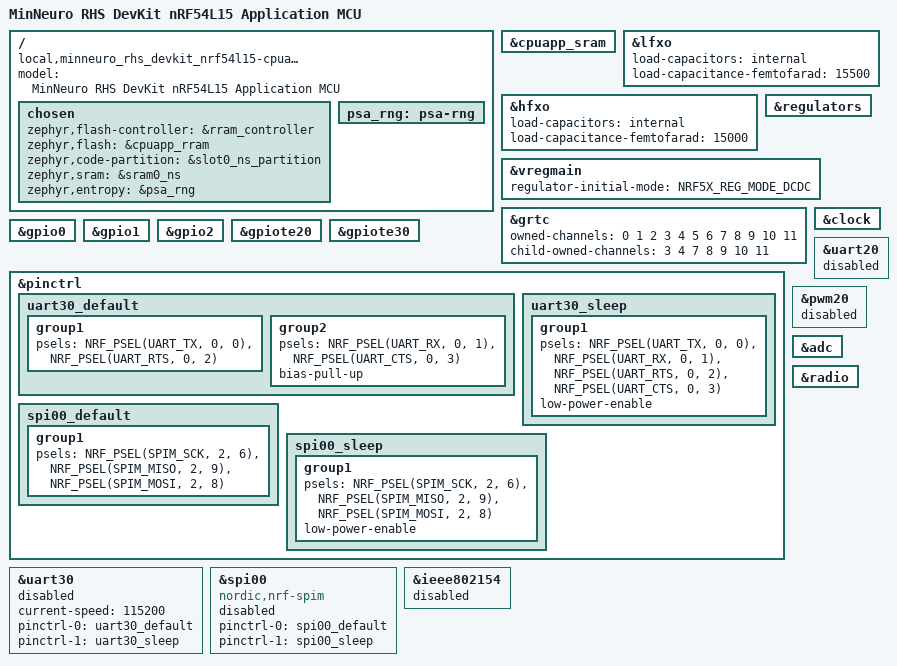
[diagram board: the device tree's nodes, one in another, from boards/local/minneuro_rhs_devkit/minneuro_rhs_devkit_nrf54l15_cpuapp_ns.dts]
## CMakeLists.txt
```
# SPDX-License-Identifier: Apache-2.0

cmake_minimum_required(VERSION 3.20.0)

list(APPEND BOARD_ROOT ${CMAKE_CURRENT_SOURCE_DIR})

find_package(Zephyr REQUIRED HINTS $ENV{ZEPHYR_BASE})
project(hello_world)

if(TARGET modules__fatfs)
  get_filename_component(FATFS_MODULE_DIR "$ENV{ZEPHYR_BASE}/../modules/fs/fatfs" ABSOLUTE)
  set_property(TARGET modules__fatfs PROPERTY SOURCES
    ${FATFS_MODULE_DIR}/ff.c
    ${FATFS_MODULE_DIR}/option/ffunicode.c
  )
  target_compile_definitions(modules__fatfs PRIVATE
    ZEPHYR_CONFIG_OVERRIDE=file_fatfs_config.h
  )
endif()

FILE(GLOB app_sources CONFIGURE_DEPENDS
  src/*.c
  src/inc/*.h
  neuro/*.c
  neuro/inc/*.h
  driver/*.c
  driver/*.h
)
# Zephyr SPI DAC shim — unused: stim uses dac80501.c + dac80501_hal via spim00_bus only.
list(FILTER app_sources EXCLUDE REGEX ".*/dac_dac80501_spi\\.c$")
target_sources(app PRIVATE ${app_sources} src/main.c)
target_include_directories(app PRIVATE ${CMAKE_CURRENT_SOURCE_DIR})
```

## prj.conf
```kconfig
# 先把所有日志/控制台关掉（很多卡死发生在串口/console init）
CONFIG_LOG=y
CONFIG_CONSOLE=n
CONFIG_UART_CONSOLE=n
CONFIG_PRINTK=y
CONFIG_SERIAL=n
CONFIG_USE_SEGGER_RTT=y
CONFIG_SHELL_BACKEND_RTT=n
# Log goes to SEGGER RTT only (UART console is disabled). Viewer must attach to Terminal 0.
# DROP mode silently discards logs when RTT FIFO is full or host attaches late — use OVERWRITE
# during bring-up so the latest lines survive in the circular buffer.
CONFIG_LOG_MODE_IMMEDIATE=y
CONFIG_SEGGER_RTT_BUFFER_SIZE_UP=32768
CONFIG_LOG_BACKEND_RTT_MODE_DROP=n
CONFIG_LOG_BACKEND_RTT_MODE_OVERWRITE=y
CONFIG_LOG_BACKEND_RTT_MESSAGE_SIZE=256

# printk/printf 支持 float
CONFIG_CBPRINTF_NANO=n
CONFIG_CBPRINTF_FP_SUPPORT=y

# flash / NVS / settings 全关
CONFIG_FLASH=n
CONFIG_FLASH_MAP=n
CONFIG_NVS=n
CONFIG_SETTINGS=n
CONFIG_FCB=n

# FatFs (ELM) — 纯库，不依赖 Zephyr SD/SPI/diskaccess 驱动
# SD SPI 协议和磁盘 I/O 完全在 driver/file.c 里自己实现
CONFIG_FILE_SYSTEM=y
CONFIG_FAT_FILESYSTEM_ELM=y
CONFIG_FS_FATFS_LFN=y
CONFIG_FS_FATFS_MAX_LFN=255
CONFIG_FS_FATFS_MOUNT_MKFS=y
CONFIG_FS_FATFS_CUSTOM_MOUNT_POINT_COUNT=1
CONFIG_FS_FATFS_CUSTOM_MOUNT_POINTS="0"

# SPIM00: spim00_bus + nrfx only (SD HAL, dac80501_hal, ks1092). DTS &spi00 disabled.
CONFIG_NRFX_SPIM=y
CONFIG_SPI=n
CONFIG_DAC=n

# 不启用 Zephyr 的 SD/MMC/diskaccess 栈
# CONFIG_DISK_DRIVER_SDMMC 和 CONFIG_SDMMC_STACK 均不开启

# 先别让任何低频时钟/外设复杂初始化影响（RC 32k，稳定）
# CONFIG_CLOCK_CONTROL=y
# CONFIG_CLOCK_CONTROL_NRF=y
# CONFIG_CLOCK_CONTROL_NRF_K32SRC_RC=y
# CONFIG_CLOCK_CONTROL_NRF_K32SRC_XTAL=n
# CONFIG_CLOCK_CONTROL_NRF_K32SRC_SYNTH=n

###########################################################

################################
# Bluetooth Core
################################
CONFIG_BT=y
CONFIG_BT_PERIPHERAL=y
CONFIG_BT_DEVICE_NAME="MinNeuro R1"

################################
# GATT / 需要 MTU 交换
################################
CONFIG_BT_GATT_CLIENT=y

################################
# PHY / DLE
################################
CONFIG_BT_CTLR_PHY_2M=y
CONFIG_BT_USER_PHY_UPDATE=y

CONFIG_BT_USER_DATA_LEN_UPDATE=y
CONFIG_BT_CTLR_DATA_LENGTH_MAX=251

################################
# MTU = 500（关键）
################################
CONFIG_BT_L2CAP_TX_MTU=500


# ATT MTU 交换：两边都至少 503（ATT=MTU，L2CAP/SDU 还要开销）
# Zephyr 的 ATT MTU 由 L2CAP_TX_MTU 驱动，但 buffer 也必须够
CONFIG_BT_BUF_ACL_TX_SIZE=500
CONFIG_BT_BUF_ACL_RX_SIZE=500

# 为了稳定，建议把 TX buffer 数量略抬高（默认有时不够导致 -ENOMEM）
CONFIG_BT_BUF_ACL_TX_COUNT=10
CONFIG_BT_BUF_EVT_RX_COUNT=11

# ATT TX pool buffer 数量（att_pool, 直接决定 K_NO_WAIT 下能否拿到 buffer）
# 默认 = BT_BUF_ACL_TX_COUNT。sys_work_q 上 notify 使用 K_NO_WAIT，
# 5ms × 2 char × 500B / 2M PHY pipeline 容易耗尽，需要显式扩大。
CONFIG_BT_ATT_TX_COUNT=10

################################
# Services
################################
CONFIG_BT_BAS=y
CONFIG_BT_DIS=y


################################
# DIS 信息（不走 settings）
################################
CONFIG_BT_DIS_PNP=n
CONFIG_BT_DIS_MODEL="MinNeuro R1"
CONFIG_BT_DIS_MANUF="MinNeuro"

CONFIG_BT_DIS_SERIAL_NUMBER=y
CONFIG_BT_DIS_SERIAL_NUMBER_STR="F.A000001"

CONFIG_BT_DIS_FW_REV=y
CONFIG_BT_DIS_FW_REV_STR="MinNeuro Firmware"
CONFIG_BT_DIS_HW_REV=y
CONFIG_BT_DIS_HW_REV_STR="MinNeuro Hardware"
CONFIG_BT_DIS_SW_REV=y
CONFIG_BT_DIS_SW_REV_STR="MinNeuro Software"

CONFIG_BT_DIS_STR_MAX=32

################################
# ❌ 明确关闭 settings（否则必炸）
################################
CONFIG_BT_SETTINGS=n
CONFIG_SETTINGS=n
CONFIG_BT_DIS_SETTINGS=n


################################
# CONFIG
################################

# looper_work_handler 运行于系统工作队列线程，适当加大其栈空间
CONFIG_SYSTEM_WORKQUEUE_STACK_SIZE=4096
# main 线程栈
CONFIG_MAIN_STACK_SIZE=2048

CONFIG_GPIO=y
CONFIG_PINCTRL=y
CONFIG_NRFX_SAADC=y
CONFIG_NRFX_SPIS=n

# CONFIG_NRFX_TIMER=y
# CONFIG_PINCTRL=y
# # CONFIG_I2C=y
# CONFIG_ADC=y
# CONFIG_NRFX_SAADC=y
# CONFIG_REBOOT=y
```

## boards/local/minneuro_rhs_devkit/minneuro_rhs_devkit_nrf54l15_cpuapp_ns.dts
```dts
/*
 * MinNeuro RHS DevKit — nRF54L15 Application MCU, non-secure image.
 * Partition layout must stay in sync with TF-M (see Nordic
 * nrf54l15_cpuapp_ns_partition.dtsi).
 */

/dts-v1/;

#define USE_NON_SECURE_ADDRESS_MAP 1

#include <arm/nordic/nrf54l15_cpuapp_ns.dtsi>

/ {
	model = "MinNeuro RHS DevKit nRF54L15 Application MCU";
	compatible = "local,minneuro_rhs_devkit_nrf54l15-cpuapp";

	chosen {
		zephyr,flash-controller = &rram_controller;
		zephyr,flash = &cpuapp_rram;
		zephyr,code-partition = &slot0_ns_partition;
		zephyr,sram = &sram0_ns;
		zephyr,entropy = &psa_rng;
	};

	/delete-node/ rng;

	psa_rng: psa-rng {
		status = "okay";
	};
};

#include <vendor/nordic/nrf54l15_cpuapp_ns_partition.dtsi>

&cpuapp_sram {
	status = "okay";
};

&lfxo {
	load-capacitors = "internal";
	load-capacitance-femtofarad = <15500>;
};

&hfxo {
	load-capacitors = "internal";
	load-capacitance-femtofarad = <15000>;
};

&regulators {
	status = "okay";
};

&vregmain {
	status = "okay";
	regulator-initial-mode = <NRF5X_REG_MODE_DCDC>;
};

&grtc {
	owned-channels = <0 1 2 3 4 5 6 7 8 9 10 11>;
	child-owned-channels = <3 4 7 8 9 10 11>;
	status = "okay";
};

&clock {
	status = "okay";
};

&gpio0 {
	status = "okay";
};

&gpio1 {
	status = "okay";
};

&gpio2 {
	status = "okay";
};

&gpiote20 {
	status = "okay";
};

&gpiote30 {
	status = "okay";
};

&pinctrl {
	/* TF-M secure image uses UARTE30; match nRF54L15 DK pins unless your schematic differs. */
	uart30_default: uart30_default {
		group1 {
			psels = <NRF_PSEL(UART_TX, 0, 0)>,
				<NRF_PSEL(UART_RTS, 0, 2)>;
		};

		group2 {
			psels = <NRF_PSEL(UART_RX, 0, 1)>,
				<NRF_PSEL(UART_CTS, 0, 3)>;
			bias-pull-up;
		};
	};

	uart30_sleep: uart30_sleep {
		group1 {
			psels = <NRF_PSEL(UART_TX, 0, 0)>,
				<NRF_PSEL(UART_RX, 0, 1)>,
				<NRF_PSEL(UART_RTS, 0, 2)>,
				<NRF_PSEL(UART_CTS, 0, 3)>;
			low-power-enable;
		};
	};

	spi00_default: spi00_default {
		group1 {
			psels = <NRF_PSEL(SPIM_SCK, 2, 6)>,
				<NRF_PSEL(SPIM_MISO, 2, 9)>,
				<NRF_PSEL(SPIM_MOSI, 2, 8)>;
		};
	};

	spi00_sleep: spi00_sleep {
		group1 {
			psels = <NRF_PSEL(SPIM_SCK, 2, 6)>,
				<NRF_PSEL(SPIM_MISO, 2, 9)>,
				<NRF_PSEL(SPIM_MOSI, 2, 8)>;
			low-power-enable;
		};
	};
};

&uart20 {
	status = "disabled";
};

&uart30 {
	/* Disable Zephyr driver in NS; TF-M still requires this node + pinctrl for secure build. */
	status = "disabled";

	current-speed = <115200>;
	pinctrl-0 = <&uart30_default>;
	pinctrl-1 = <&uart30_sleep>;
	pinctrl-names = "default", "sleep";
};

&pwm20 {
	status = "disabled";
};

/*
 * SPIM00 is owned by application HAL: spim00_bus (SD file_nrf54_hal, dac80501_hal, ks1092).
 * Keep Zephyr &spi00 disabled so spi_nrfx does not share the same nrfx instance.
 */
&spi00 {
	compatible = "nordic,nrf-spim";
	status = "disabled";
	pinctrl-0 = <&spi00_default>;
	pinctrl-1 = <&spi00_sleep>;
	pinctrl-names = "default", "sleep";
};

&adc {
	status = "okay";
};

&radio {
	status = "okay";
};

&ieee802154 {
	status = "disabled";
};
```

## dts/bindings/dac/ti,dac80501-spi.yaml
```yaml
# Copyright (c) 2025 MinNeuro
# SPDX-License-Identifier: Apache-2.0

description: |
  TI DAC80501 16-bit DAC (SPI variant).
  SPI frame format: 24-bit (8-bit register address + 16-bit data).
  CPOL=0, CPHA=1 (SPI mode 1).

compatible: "ti,dac80501-spi"

include: [dac-controller.yaml, spi-device.yaml]

properties:
  voltage-reference:
    type: string
    required: true
    enum:
      - "internal"
      - "external"
    description: |
      DAC voltage reference select: either internal (2.5 V) or external.

  output-gain:
    type: string
    required: true
    enum:
      - "mul2"
      - "mul1"
      - "div2"
      - "div2-x2"
    description: |
      Output voltage range control.
        mul2:    VREF * 2 (buffer gain 2x, ref divider off)  → 5.0 V
        mul1:    VREF * 1 (buffer gain 1x, ref divider off)  → 2.5 V
        div2:    VREF / 2 (buffer gain 1x, ref divider on)   → 1.25 V
        div2-x2: VREF/2 * 2 (ref divider on + buffer gain 2x) → 2.5 V
                 Safe for 3.3 V rails (avoids REF-ALARM).
```

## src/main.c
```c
#include <zephyr/kernel.h>
#include <zephyr/logging/log.h>
#include <zephyr/sys/printk.h>

#include "driver/spim00_bus.h"
#include "inc/sd_fs_test.h"
#include "inc/stim_test.h"

#include "neuro/inc/neuro_ctrl.h"

LOG_MODULE_REGISTER(main_app, LOG_LEVEL_INF);

int main(void)
{
  int err;

  k_msleep(300); /* Wait for power to stabilize */

  printk("\n>>> main alive (printk to RTT; UART console disabled)\n");

  /* One-time SPIM00 (nrfx) init before any EEG / stim / SD task touches the bus (idempotent). */
  err = spim00_bus_init();
  if (err != 0) {
    LOG_ERR("spim00_bus_init failed (%d)", err);
  }

  /*
   * SPI / bus stress layout (adjust priorities vs. sd_fs_test / driver mutex):
   *   sd_fs_test  — mount + FAT I/O on SPIM00 (prio 3, sd_fs_test.c)
   *   eeg_test    — eeg_manager timer + frame reads (prio 5, eeg_test.c)
   *   stim_test   — DAC / neuro waveform on SPI (prio 6, stim_test.c)
   *
   * Real concurrency correctness depends on spim00_bus (or Zephyr spi00)
   * arbitration and chip-select isolation; these threads deliberately overlap.
   */
  // LOG_INF("=== start SD FAT smoke thread ===");
  err = sd_fs_test_start();
  if (err != 0) {
    LOG_ERR("sd_fs_test_start failed (%d)", err);
  }

  // LOG_INF("=== start EEG test thread ===");
  // err = eeg_test_start();
  // if (err != 0) {
  //   LOG_ERR("eeg_test_start failed (%d)", err);
  // }

  // LOG_INF("=== start stim test thread ===");
  // err = stim_test_start();
  // if (err != 0) {
  //   LOG_ERR("stim_test_start failed (%d)", err);
  // }

  /*
   * Enables neuro_ctrl_thread_main idle→run: sets running=true after neuro_ctrl_init.
   * Idempotent init if stim_test_start already succeeded; retries init if stim failed earlier.
   * Note: simultaneous stim_test DAC streaming and neuro wave_ctrl DAC use must be coordinated.
   */
  // err = neuro_ctrl_start();
  if (err != 0) {
    LOG_ERR("neuro_ctrl_start failed (%d)", err);
  } else {
    LOG_INF("neuro_ctrl main loop enabled (running=true)");
  }

  for (;;) {
    //LOG_INF("keep working :(");
    k_sleep(K_FOREVER);
  }
//never reach here
  return 0;
}
```

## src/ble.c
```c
#include "inc/ble.h"

#include "inc/minneuro_mode.h"

#include <zephyr/sys/util.h>
#include <zephyr/settings/settings.h>
#include <zephyr/bluetooth/bluetooth.h>
#include <zephyr/bluetooth/gatt.h>
#include <zephyr/logging/log.h>

#include "inc/ble_conn.h"
#include "inc/ble_bat.h"
#include "inc/ble_debug.h"
#include "inc/ble_aaaa.h"

LOG_MODULE_REGISTER(ble, LOG_LEVEL_INF);

void mtu_updated(struct bt_conn *conn, uint16_t tx, uint16_t rx)
{
	printk("Updated MTU: TX: %d RX: %d bytes\n", tx, rx);
}
static struct bt_gatt_cb gatt_callbacks = {.att_mtu_updated = mtu_updated};

int ble_init()
{
  int err = 0;
  
  // Bluetooth
  err = bt_enable(NULL);
  if (err) {
    return err;
  }
  bt_gatt_cb_register(&gatt_callbacks);
  // // // LOG_INF("Bluetooth init success.");
  // // if (IS_ENABLED(CONFIG_BT_SETTINGS))
  // // {
  // //   settings_load();
  // //   // LOG_INF("Settings init success.");
  // // }

  err = ble_aaaa_init();
  if (err) {
    return err;
  }

#if MINNEURO_DEBUG_MODE && !MINNEURO_STIM_TEST_MODE
  err = ble_debug_init();
  if (err) {
    LOG_WRN("debug BLE service init failed (%d), continuing without debug service", err);
  }
#endif

  err = ble_bat_init();
  if (err) {
    err = 0;
  }
  
  err = ble_adv_init();
  if (err) {
    return err;
  }
  
  err = ble_adv_start();
  if (err) {
    return err;
  }

  return 0;
}

int ble_uninit()
{
  return 0;
}
```

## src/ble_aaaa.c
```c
#ifndef ENABLE_FACA_SERVICE__
#define ENABLE_FACA_SERVICE__

#include "inc/ble_aaaa_priv.h"

#include "inc/bsp.h"
#include "neuro/inc/eeg_manager.h"

#include <zephyr/bluetooth/bluetooth.h>
#include <zephyr/bluetooth/hci.h>
#include <zephyr/bluetooth/conn.h>
#include <zephyr/bluetooth/uuid.h>
#include <zephyr/bluetooth/gatt.h>

#include <zephyr/logging/log.h>
LOG_MODULE_REGISTER(aaaa, LOG_LEVEL_INF);


/*
 **************************************************
 *                                                *
 *  Bluetooth LE.                                 *
 *                                                *
 **************************************************
 */

// SERVICE: AAAA
struct bt_uuid_128 aaaa_service_uuid = BT_UUID_INIT_128(BT_UUID_128_ENCODE(0x0000AAAA, 0x0000, 0x1000, 0x8000, 0x00805f9b34fb));

// EMG/ECG/EOG/EEG Characteristics
//// AAF0: READ STATE
struct bt_uuid_128 aaf0_char_uuid = BT_UUID_INIT_128(BT_UUID_128_ENCODE(0x0000AAF0, 0x0000, 0x1000, 0x8000, 0x00805f9b34fb));
//// AAFF: STREAM
struct bt_uuid_128 aaff_char_uuid = BT_UUID_INIT_128(BT_UUID_128_ENCODE(0x0000AAFF, 0x0000, 0x1000, 0x8000, 0x00805f9b34fb));

// IMU/MAG Characteristics
//// AAE0: READ STATE
struct bt_uuid_128 aae0_char_uuid = BT_UUID_INIT_128(BT_UUID_128_ENCODE(0x0000AAE0, 0x0000, 0x1000, 0x8000, 0x00805f9b34fb));
//// AAEF: STREAM
struct bt_uuid_128 aaef_char_uuid = BT_UUID_INIT_128(BT_UUID_128_ENCODE(0x0000AAEF, 0x0000, 0x1000, 0x8000, 0x00805f9b34fb));

// PPG Characteristics
//// AAD0: READ STATE
struct bt_uuid_128 aad0_char_uuid = BT_UUID_INIT_128(BT_UUID_128_ENCODE(0x0000AAD0, 0x0000, 0x1000, 0x8000, 0x00805f9b34fb));
//// AADF: STREAM
struct bt_uuid_128 aadf_char_uuid = BT_UUID_INIT_128(BT_UUID_128_ENCODE(0x0000AADF, 0x0000, 0x1000, 0x8000, 0x00805f9b34fb));


BT_GATT_SERVICE_DEFINE(aaaa_service,
  BT_GATT_PRIMARY_SERVICE(&aaaa_service_uuid),
  /** EMG/ECG/EOG/EEG **/
  // State.
  BT_GATT_CHARACTERISTIC(&aaf0_char_uuid.uuid, BT_GATT_CHRC_WRITE | BT_GATT_CHRC_WRITE_WITHOUT_RESP | BT_GATT_CHRC_NOTIFY | BT_GATT_CHRC_READ,
            BT_GATT_PERM_READ | BT_GATT_PERM_WRITE, ble_on_aaf0_read_request, ble_on_aaf0_write_request, NULL),
  BT_GATT_CCC(ble_ccc_cfg_changed_aaf0, BT_GATT_PERM_READ | BT_GATT_PERM_WRITE),
  // Stream.
  BT_GATT_CHARACTERISTIC(&aaff_char_uuid.uuid, BT_GATT_CHRC_NOTIFY | BT_GATT_CHRC_READ,
            BT_GATT_PERM_READ | BT_GATT_PERM_WRITE, NULL, NULL, NULL),
  BT_GATT_CCC(ble_ccc_cfg_changed_aaff, BT_GATT_PERM_READ | BT_GATT_PERM_WRITE),

  /** IMU/MAG **/
  // State.
  BT_GATT_CHARACTERISTIC(&aae0_char_uuid.uuid, BT_GATT_CHRC_WRITE | BT_GATT_CHRC_WRITE_WITHOUT_RESP | BT_GATT_CHRC_NOTIFY | BT_GATT_CHRC_READ,
            BT_GATT_PERM_READ | BT_GATT_PERM_WRITE, ble_on_aae0_read_request, ble_on_aae0_write_request, NULL),
  BT_GATT_CCC(ble_ccc_cfg_changed_aae0, BT_GATT_PERM_READ | BT_GATT_PERM_WRITE),
  // Stream.
  BT_GATT_CHARACTERISTIC(&aaef_char_uuid.uuid, BT_GATT_CHRC_NOTIFY | BT_GATT_CHRC_READ,
            BT_GATT_PERM_READ | BT_GATT_PERM_WRITE, NULL, NULL, NULL),
  BT_GATT_CCC(ble_ccc_cfg_changed_aaef, BT_GATT_PERM_READ | BT_GATT_PERM_WRITE),
);


/*
 **************************************************
 *                                                *
 *  Worker Loop                                 *
 *                                                *
 **************************************************
*/

static mpu_sync_frame_t sync_frame[2];
volatile int sync_frame_index = 0;
volatile bool sync_frame_ready = false;
volatile uint32_t sync_seq = 0;
static uint32_t eeg_seq = 0;

int mpu_irq_on_rx_ready(mpu_sync_frame_t * frame)
{
  /* struct 赋值 = memcpy，完整值拷贝到全局静态数组，安全。
   * frame 指向 mpu_irq.c 内的 static parsed_frame，不会随函数返回而消失。*/
  sync_frame_index = (sync_frame_index + 1) % 2;
  sync_frame[sync_frame_index] = *frame;
  sync_frame_ready = true;
  sync_seq++;
  return 0;
}

// Looper

#define LOOPER_INTERVAL         1     // 1ms

static void looper_work_handler(struct k_work *work);

static K_WORK_DELAYABLE_DEFINE(looper_work, looper_work_handler);

static void looper_work_handler(struct k_work *work)
{
  eeg_manager_frame_t eeg_frame;
  static mpu_eeg_data_t eeg_notify_frame[TASK_EEG_FRAME_SIZE];
  uint8_t eeg_samples_to_send;

  // DREADY.
  // if (sync_frame_ready) {
  //   sync_frame_ready = false;
  //   const mpu_sync_frame_t *frame = &sync_frame[sync_frame_index]; // 用指针，避免栈上拷贝 ~588 字节
  //   ble_aaff_notify_commit_mpu(sync_seq, frame->eegs, frame->eeg_length, frame->eeg_channels);
  //   ble_aaef_notify_commit_mpu(sync_seq, frame->imus, frame->imu_length, frame->imu_channels);
  // }

  // static mpu_sync_frame_t mpu_sync_frame;
  // static int dready_ms = 0;
  // dready_ms++;
  // bool ready = nrf_gpio_pin_read(PIN_MPU_DREADY);
  // if (ready) {
  //   dready_ms = 0;
  //   // read by SPI.
  //   int err = mpu_sync_read(&mpu_sync_frame);
  //   if (!err) {
  //     // notify to BLE.
  //     ble_aaff_notify_commit_mpu(&mpu_sync_frame.eegs, mpu_sync_frame.eeg_length, mpu_sync_frame.eeg_channels);
  //     ble_aaef_notify_commit_mpu(&mpu_sync_frame.imus, mpu_sync_frame.imu_length);
  //   }
  // }

  if (ble_aaff_can_accept_frame() && (eeg_manager_read_frame(&eeg_frame) == 0)) {
    eeg_samples_to_send = eeg_frame.sample_count;
    if (eeg_samples_to_send > TASK_EEG_FRAME_SIZE) {
      eeg_samples_to_send = TASK_EEG_FRAME_SIZE;
    }

    for (uint8_t sample_index = 0; sample_index < eeg_samples_to_send; ++sample_index) {
      for (uint8_t channel_index = 0; channel_index < TASK_EEG_CHANNEL_SIZE; ++channel_index) {
        eeg_notify_frame[sample_index].volt[channel_index] =
          (uint16_t)eeg_frame.volts[sample_index][channel_index];
      }
    }

    (void)ble_aaff_notify_commit_mpu(eeg_seq++, eeg_notify_frame, eeg_samples_to_send, TASK_EEG_CHANNEL_SIZE);
  }

  ble_aaff_loop();
  ble_aaef_loop();
	k_work_reschedule(k_work_delayable_from_work(work), K_MSEC(LOOPER_INTERVAL));
}

int ble_aaaa_init()
{
  int err = 0;
  err = ble_aaff_init();

  // err = k_work_schedule(&looper_work, K_NO_WAIT);
  err = k_work_schedule(&looper_work, K_MSEC(200)); // 延迟 200ms 启动，确保尽可能在最后时刻
  return 0;
}

#endif
```

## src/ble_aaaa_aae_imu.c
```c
#ifndef BLE_AAAA_AAE_IMU_C__
#define BLE_AAAA_AAE_IMU_C__

#include "inc/ble_aaaa_priv.h"

#include <zephyr/logging/log.h>
LOG_MODULE_REGISTER(AAE, LOG_LEVEL_INF);

#define STATE_CODE_LEN 20
#define STREAM_BUFFER_MAX_LEN 512

typedef struct {
  uint8_t state_codes[STATE_CODE_LEN];
  uint8_t stream_buffer[STREAM_BUFFER_MAX_LEN];
  uint16_t stream_buffer_len;
  volatile bool stream_ready;
  // Notifications:
  volatile bool aae0_notify_enabled;
  volatile bool aaef_notify_enabled;
} aae_t;

static volatile aae_t state_aae;

void ble_ccc_cfg_changed_aae0(const struct bt_gatt_attr *attr, uint16_t value)
{
	ARG_UNUSED(attr);
	state_aae.aae0_notify_enabled = (value == BT_GATT_CCC_NOTIFY);
	LOG_INF("Notification[aae0] %s", state_aae.aae0_notify_enabled ? "enabled" : "disabled");
}

void ble_ccc_cfg_changed_aaef(const struct bt_gatt_attr *attr, uint16_t value)
{
	ARG_UNUSED(attr);
	state_aae.aaef_notify_enabled = (value == BT_GATT_CCC_NOTIFY);
	LOG_INF("Notification[aaeF] %s", state_aae.aaef_notify_enabled ? "enabled" : "disabled");
}

ssize_t ble_on_aae0_read_request(struct bt_conn *conn, const struct bt_gatt_attr *attr, void *buf, uint16_t len, uint16_t offset)
{
  // const char *value = attr->user_data; // NULL
  const char *value = (const char *)state_aae.state_codes;
  return bt_gatt_attr_read(conn, attr, buf, len, offset, value, STATE_CODE_LEN);
}

ssize_t ble_on_aae0_write_request(struct bt_conn *conn, const struct bt_gatt_attr *attr, const void *buf, uint16_t len, uint16_t offset, uint8_t flags)
{

  LOG_INF("payload len: %d", len);
  if (len == 1) { // debug mode
    int err = 0; // xx_verify();
    LOG_INF("faca: debug verify: %02x", err);
    return 0;
  }
  /**
   * 
   * Request Payload Parser & Resp.
   * 
  */
  uint8_t * data = (uint8_t *)buf;
  uint16_t request_id = (uint16_t)(data[0] << 8) | (data[1] & 0xFF);
  uint8_t method = data[2] & 0xFF;

  return len;
}

int ble_aaef_notify_commit(uint8_t * data, uint8_t len)
{
  // copy:
  for (int i = 0; i < len; i++) {
    state_aae.stream_buffer[i] = data[i];
  }
  state_aae.stream_buffer_len = len;
  state_aae.stream_ready = true;
  return 0;
}

int ble_aaef_notify_commit_mpu(uint32_t seq, mpu_imu_data_t * data, uint8_t len, uint8_t ch)
{
  // printk("Notify IMU: seq=%u, len=%u, ch=%u\n", seq, len, ch);
  uint16_t index = 0;
  // spec code:
  state_aae.stream_buffer[index++] = 0x72;
  // seq:
  state_aae.stream_buffer[index++] = (seq >> 24) & 0xFF;
  state_aae.stream_buffer[index++] = (seq >> 16) & 0xFF;
  state_aae.stream_buffer[index++] = (seq >> 8) & 0xFF;
  state_aae.stream_buffer[index++] = (seq) & 0xFF;
  // len:
  state_aae.stream_buffer[index++] = len;                           // frame length.

  for (uint8_t i = 0; i < len; i++) {
    state_aae.stream_buffer[index++] = (data[i].temperature >> 8) & 0xFF; // temperature h.
    state_aae.stream_buffer[index++] = (data[i].temperature & 0xFF);      // temperature l.
    state_aae.stream_buffer[index++] = (data[i].ax >> 8) & 0xFF;          // ax h.
    state_aae.stream_buffer[index++] = (data[i].ax & 0xFF);               // ax l.
    state_aae.stream_buffer[index++] = (data[i].ay >> 8) & 0xFF;          // ay h.
    state_aae.stream_buffer[index++] = (data[i].ay & 0xFF);               // ay l.
    state_aae.stream_buffer[index++] = (data[i].az >> 8) & 0xFF;          // az h.
    state_aae.stream_buffer[index++] = (data[i].az & 0xFF);               // az l.
    state_aae.stream_buffer[index++] = (data[i].gx >> 8) & 0xFF;          // gx h.
    state_aae.stream_buffer[index++] = (data[i].gx & 0xFF);               // gx l.
    state_aae.stream_buffer[index++] = (data[i].gy >> 8) & 0xFF;          // gy h.
    state_aae.stream_buffer[index++] = (data[i].gy & 0xFF);               // gy l.
    state_aae.stream_buffer[index++] = (data[i].gz >> 8) & 0xFF;          // gz h.
    state_aae.stream_buffer[index++] = (data[i].gz & 0xFF);               // gz l.
    state_aae.stream_buffer[index++] = (data[i].mx >> 8) & 0xFF;          // mx h.
    state_aae.stream_buffer[index++] = (data[i].mx & 0xFF);               // mx l.
    state_aae.stream_buffer[index++] = (data[i].my >> 8) & 0xFF;          // my h.
    state_aae.stream_buffer[index++] = (data[i].my & 0xFF);               // my l.
    state_aae.stream_buffer[index++] = (data[i].mz >> 8) & 0xFF;          // mz h.
    state_aae.stream_buffer[index++] = (data[i].mz & 0xFF);               // mz l.
    if (ch >= 13) {
      state_aae.stream_buffer[index++] = (data[i].yaw >> 8) & 0xFF;       // yaw h.
      state_aae.stream_buffer[index++] = (data[i].yaw & 0xFF);            // yaw l.
      state_aae.stream_buffer[index++] = (data[i].pitch >> 8) & 0xFF;     // pitch h.
      state_aae.stream_buffer[index++] = (data[i].pitch & 0xFF);          // pitch l.
      state_aae.stream_buffer[index++] = (data[i].roll >> 8) & 0xFF;      // roll h.
      state_aae.stream_buffer[index++] = (data[i].roll & 0xFF);           // roll l.
    }
  }
  state_aae.stream_buffer_len = index;
  state_aae.stream_ready = true;
  return 0;
}

int ble_aaef_loop()
{
  // if ready
  if (!state_aae.aaef_notify_enabled) {
    return -1;
  }
  if (!state_aae.stream_ready) {
    return -2;
  }
  // printk("len: %u\n", state_aae.stream_buffer_len);
  int err = bt_gatt_notify(NULL, &aaaa_service.attrs[IMU_AAEF_INDEX], (uint8_t*)&(state_aae.stream_buffer), state_aae.stream_buffer_len);
  if (err) {
    printk("Failed to notify IMU data: %d\n", err);
    return err;
  }
  return 0;
}

#endif
```

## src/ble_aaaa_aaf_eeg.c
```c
#ifndef BLE_AAAA_AAE_IMU_C__
#define BLE_AAAA_AAE_IMU_C__

#include "inc/ble_aaaa_priv.h"

#include "neuro/inc/eeg_manager.h"
#include <errno.h>
#include <string.h>
#include <zephyr/kernel.h>
#include <zephyr/logging/log.h>
LOG_MODULE_REGISTER(AAF, LOG_LEVEL_INF);

// #define STATE_CODE_LEN 20
#define STREAM_BUFFER_MAX_LEN 512

typedef struct {
  // uint8_t state_codes[STATE_CODE_LEN];
  uint8_t stream_buffer[STREAM_BUFFER_MAX_LEN];
  uint16_t stream_buffer_len;
  volatile bool stream_ready;
  // Notifications:
  volatile bool aaf0_notify_enabled;
  volatile bool aaff_notify_enabled;
} aaf_t;

static volatile aaf_t state_aaf;
static struct k_work_delayable aaff_ctrl_work;
static volatile bool aaff_target_eeg_running;
static volatile bool aaff_eeg_running;
static eeg_manager_config_t aaff_pending_cfg;

// config status
typedef struct {
  volatile uint8_t  status; // 0: stop, 1: start
  volatile uint16_t sample_rate_hz; // e.g. 1000Hz;
  volatile uint16_t channel_size; // e.g. 16
  volatile uint8_t  resolution_bits; // e.g. 16
  volatile float     scale_factor; // e.g. 0.192f uV/bit 
} aaf_config_t;

static aaf_config_t aaf_config = {
  .status = 0,
  .sample_rate_hz = TASK_EEG_DEFAULT_SAMPLE_RATE_HZ,
  .channel_size = TASK_EEG_CHANNEL_SIZE,
  .resolution_bits = 16,
  .scale_factor = 0.192f,
};

#define AAF0_CONFIG_WIRE_LEN 10u

static inline void put_be16(uint8_t *dst, uint16_t v)
{
  dst[0] = (uint8_t)((v >> 8) & 0xFFu);
  dst[1] = (uint8_t)(v & 0xFFu);
}

static inline void put_be32(uint8_t *dst, uint32_t v)
{
  dst[0] = (uint8_t)((v >> 24) & 0xFFu);
  dst[1] = (uint8_t)((v >> 16) & 0xFFu);
  dst[2] = (uint8_t)((v >> 8) & 0xFFu);
  dst[3] = (uint8_t)(v & 0xFFu);
}

static uint16_t build_aaf0_config_wire(uint8_t *out)
{
  uint32_t scale_raw;

  if (!out) {
    return 0u;
  }

  out[0] = (uint8_t)aaf_config.status;
  put_be16(&out[1], (uint16_t)aaf_config.sample_rate_hz);
  put_be16(&out[3], (uint16_t)aaf_config.channel_size);
  out[5] = (uint8_t)aaf_config.resolution_bits;

  memcpy(&scale_raw, (const void *)&aaf_config.scale_factor, sizeof(scale_raw));
  put_be32(&out[6], scale_raw);

  return AAF0_CONFIG_WIRE_LEN;
}

static void ble_aaff_ctrl_work_handler(struct k_work *work)
{
  int err;

  ARG_UNUSED(work);

  if (aaff_target_eeg_running == aaff_eeg_running) {
    return;
  }

  if (aaff_target_eeg_running) {
    err = eeg_manager_start(aaff_pending_cfg);
    if (err) {
      LOG_ERR("eeg_manager_start failed: %d", err);
      aaff_eeg_running = false;
      return;
    }

    aaff_eeg_running = true;
    aaf_config.sample_rate_hz = (uint16_t)aaff_pending_cfg.sample_rate_hz;
    aaf_config.status = 1;
    LOG_INF("AAFF EEG started: sample_rate=%u", aaff_pending_cfg.sample_rate_hz);
    return;
  }

  err = eeg_manager_stop();
  if (err) {
    LOG_ERR("eeg_manager_stop failed: %d", err);
  }
  aaff_eeg_running = false;
  aaf_config.status = 0;
  state_aaf.stream_ready = false;
  LOG_INF("AAFF EEG stopped");
}

#define AAFF_CTRL_DEBOUNCE_MS 50
static inline void trigger_task_start(eeg_manager_config_t cfg) {
  aaff_pending_cfg.sample_rate_hz = cfg.sample_rate_hz;
  aaff_target_eeg_running = true;
  (void)k_work_reschedule(&aaff_ctrl_work, K_MSEC(AAFF_CTRL_DEBOUNCE_MS));
}

static inline void trigger_task_stop() {
  aaff_target_eeg_running = false;
  (void)k_work_reschedule(&aaff_ctrl_work, K_MSEC(AAFF_CTRL_DEBOUNCE_MS));
}
/// BLE:

void ble_ccc_cfg_changed_aaf0(const struct bt_gatt_attr *attr, uint16_t value)
{
	ARG_UNUSED(attr);
	state_aaf.aaf0_notify_enabled = (value == BT_GATT_CCC_NOTIFY);
	LOG_INF("Notification[AAF0] %s", state_aaf.aaf0_notify_enabled ? "enabled" : "disabled");
}

void ble_ccc_cfg_changed_aaff(const struct bt_gatt_attr *attr, uint16_t value)
{
	ARG_UNUSED(attr);

  state_aaf.aaff_notify_enabled = (value == BT_GATT_CCC_NOTIFY);
  if (!state_aaf.aaff_notify_enabled) {
    state_aaf.stream_ready = false;
  }

  LOG_INF("Notification[AAFF] %s", state_aaf.aaff_notify_enabled ? "enabled" : "disabled");
}

ssize_t ble_on_aaf0_read_request(struct bt_conn *conn, const struct bt_gatt_attr *attr, void *buf, uint16_t len, uint16_t offset)
{
  // const char *value = (const char *)state_aaf.state_codes;
  // return bt_gatt_attr_read(conn, attr, buf, len, offset, value, STATE_CODE_LEN);

  // TEST CODE (Read from SPI):

  uint8_t wire[AAF0_CONFIG_WIRE_LEN];
  uint16_t wire_len = build_aaf0_config_wire(wire);

  // const char *value = (const char *)state_aaf.state_codes;
  return bt_gatt_attr_read(conn, attr, buf, len, offset, wire, wire_len);
}

#define AAFF_METHOD_START_WITH_CONFIG 0x00
#define AAFF_METHOD_STOP              0x01

ssize_t ble_on_aaf0_write_request(struct bt_conn *conn, const struct bt_gatt_attr *attr, const void *buf, uint16_t len, uint16_t offset, uint8_t flags)
{
  ARG_UNUSED(conn);
  ARG_UNUSED(attr);
  ARG_UNUSED(offset);
  ARG_UNUSED(flags);

  LOG_INF("payload len: %d", len);
  if (len == 1) { // debug mode
    int err = eeg_manager_verify();
    LOG_INF("faca: debug verify: %02x", err);
    return 0;
  }
  /**
   * 
   * Request Payload Parser & Resp.
   * 
  */
  if (len < 3u) {
    LOG_WRN("AAFF write payload too short: %u", len);
    return len;
  }

  const uint8_t * data = (const uint8_t *)buf;
  uint16_t request_id = (uint16_t)(data[0] << 8) | (data[1] & 0xFF);
  uint8_t method = data[2] & 0xFF;

  if (method == AAFF_METHOD_START_WITH_CONFIG) {
    eeg_manager_config_t cfg = {
      .sample_rate_hz = aaf_config.sample_rate_hz,
    };

    if (len >= 5u) {
      cfg.sample_rate_hz = ((uint16_t)data[3] << 8) | data[4];
    }
    trigger_task_start(cfg);
    LOG_INF("AAFF cmd start(cfg), req=%u, sample_rate=%u", request_id, cfg.sample_rate_hz);
    return len;
  }

  if (method == AAFF_METHOD_STOP) {
    trigger_task_stop();
    LOG_INF("AAFF cmd stop, req=%u (debounced)", request_id);
    return len;
  }

  LOG_WRN("AAFF cmd unsupported: 0x%02x, req=%u", method, request_id);

  return len;
}

int ble_aaff_notify_commit(uint8_t * data, uint8_t len)
{
  // copy:
  for (int i = 0; i < len; i++) {
    state_aaf.stream_buffer[i] = data[i];
  }

  state_aaf.stream_buffer_len = len;
  state_aaf.stream_ready = true;
  return 0;
}

int ble_aaff_notify_commit_mpu(uint32_t seq, mpu_eeg_data_t * data, uint8_t len, uint16_t channel_size)
{
  uint16_t payload_len;

  if ((len == 0u) || (channel_size == 0u)) {
    return -EINVAL;
  }

  if (state_aaf.stream_ready) {
    return -EBUSY;
  }

  payload_len = (uint16_t)(8u + ((uint16_t)len * channel_size * 2u));
  if (payload_len > STREAM_BUFFER_MAX_LEN) {
    return -EMSGSIZE;
  }

  uint16_t index = 0;
  // spec code:
  state_aaf.stream_buffer[index++] = 0x73;
  // seq:
  state_aaf.stream_buffer[index++] = (seq >> 24) & 0xFF;
  state_aaf.stream_buffer[index++] = (seq >> 16) & 0xFF;
  state_aaf.stream_buffer[index++] = (seq >> 8) & 0xFF;
  state_aaf.stream_buffer[index++] = (seq) & 0xFF;
  // len:
  state_aaf.stream_buffer[index++] = len;                           // frame length.
  // ch:
  state_aaf.stream_buffer[index++] = (channel_size >> 8) & 0xFF;    // channel size l.
  state_aaf.stream_buffer[index++] = (channel_size & 0xFF);         // channel size r.

  uint16_t temp = 0;
  for (uint16_t i = 0; i < len; i++) {
    for (uint16_t j = 0; j < channel_size; j++) {
      temp = data[i].volt[j];
      state_aaf.stream_buffer[index++] = (temp >> 8) & 0xFF; // volt l.
      state_aaf.stream_buffer[index++] = (temp & 0xFF);      // volt r.
    }
  }
  state_aaf.stream_buffer_len = index;
  state_aaf.stream_ready = true;
  return 0;
}

int ble_aaff_loop()
{
  // if ready
  if (!state_aaf.aaff_notify_enabled) {
    return -1;
  }
  if (!state_aaf.stream_ready) {
    return -2;
  }
  // printk("len: %u\n", state_aaf.stream_buffer_len);
  int err = bt_gatt_notify(NULL, &aaaa_service.attrs[EEG_AAFF_INDEX], (uint8_t*)&(state_aaf.stream_buffer), state_aaf.stream_buffer_len);
  if (err) {
    // retry once:
    // printk("Failed to notify EEG data: %d\n", err);
    err = bt_gatt_notify(NULL, &aaaa_service.attrs[EEG_AAFF_INDEX], (uint8_t*)&(state_aaf.stream_buffer), state_aaf.stream_buffer_len);
    if (err) {
      return err;
    }
  }
  state_aaf.stream_ready = false;
  return 0;
}

bool ble_aaff_can_accept_frame(void)
{
  return state_aaf.aaff_notify_enabled && !state_aaf.stream_ready;
}

int ble_aaff_init()
{
  k_work_init_delayable(&aaff_ctrl_work, ble_aaff_ctrl_work_handler);
  return 0;
}

#endif
```

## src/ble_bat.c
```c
#include "inc/ble_bat.h"

#include <zephyr/bluetooth/services/bas.h>
#include <zephyr/kernel.h>
#include <zephyr/logging/log.h>

#include "driver/battery.h"

LOG_MODULE_REGISTER(ble_bat, LOG_LEVEL_INF);

enum {
  BLE_BAT_REFRESH_INTERVAL_MS = 1000,
};

struct ble_bat_runtime {
  bool initialized;
  bool has_level;
  uint8_t level;
};

static struct ble_bat_runtime s_ble_bat;

static void ble_bat_work_handler(struct k_work *work);
static K_WORK_DELAYABLE_DEFINE(s_ble_bat_work, ble_bat_work_handler);

static void ble_bat_refresh_once(void)
{
  battery_measurement_t measurement;
  int err;

  err = battery_refresh(&measurement);
  if (err) {
    LOG_WRN("battery refresh failed: %d", err);
    return;
  }

  if (!s_ble_bat.has_level || s_ble_bat.level != measurement.level_pct) {
    err = bt_bas_set_battery_level(measurement.level_pct);
    if (err) {
      LOG_WRN("battery level publish failed: %d", err);
      return;
    }

    s_ble_bat.level = measurement.level_pct;
    s_ble_bat.has_level = true;
  }
}

static void ble_bat_work_handler(struct k_work *work)
{
  ARG_UNUSED(work);

  ble_bat_refresh_once();
  (void)k_work_reschedule(&s_ble_bat_work, K_MSEC(BLE_BAT_REFRESH_INTERVAL_MS));
}

int ble_bat_init(void)
{
  int err;

  if (s_ble_bat.initialized) {
    return 0;
  }

  err = battery_init();
  if (err) {
    return err;
  }

  ble_bat_refresh_once();
  (void)k_work_schedule(&s_ble_bat_work, K_MSEC(BLE_BAT_REFRESH_INTERVAL_MS));

  s_ble_bat.initialized = true;
  return 0;
}

uint8_t ble_bat_get_level(void)
{
  return s_ble_bat.level;
}
```

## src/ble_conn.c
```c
#include "inc/ble_conn.h"
#include "inc/minneuro_mode.h"

#include <zephyr/kernel.h>
#include <zephyr/bluetooth/bluetooth.h>
#include <zephyr/bluetooth/hci.h>
#include <zephyr/bluetooth/conn.h>
#include <zephyr/bluetooth/gatt.h>
#include <zephyr/bluetooth/uuid.h>

#include <zephyr/logging/log.h>
LOG_MODULE_REGISTER(blec, LOG_LEVEL_INF);

#define DEVICE_NAME     CONFIG_BT_DEVICE_NAME
#define DEVICE_NAME_LEN (sizeof(DEVICE_NAME) - 1)

static volatile bool device_connected = false;
static struct k_work_delayable adv_restart_work;

#define ADV_RESTART_DELAY_MS 100u
#define ADV_RESTART_RETRY_MS 200u

/* Advertising data (ADV) */
static const struct bt_data ad[] = {
	BT_DATA_BYTES(BT_DATA_FLAGS, (BT_LE_AD_GENERAL | BT_LE_AD_NO_BREDR)),

	BT_DATA_BYTES(BT_DATA_UUID16_ALL,
#if MINNEURO_DEBUG_MODE
		      BT_UUID_16_ENCODE(0xAAAB),            /* Debug Service */
#endif
		      BT_UUID_16_ENCODE(0xAAAA),            /* AAAA */
		      BT_UUID_16_ENCODE(BT_UUID_BAS_VAL),   /* Battery Service */
		      BT_UUID_16_ENCODE(BT_UUID_DIS_VAL)),  /* Device Information Service */
};

/* Scan response data (SCAN_RSP) */
static const struct bt_data sd[] = {
	BT_DATA(BT_DATA_NAME_COMPLETE, DEVICE_NAME, DEVICE_NAME_LEN),
};

static void connected(struct bt_conn *conn, uint8_t conn_err)
{
	int err;
	struct bt_conn_info info;
	char addr[BT_ADDR_LE_STR_LEN];

	bt_addr_le_to_str(bt_conn_get_dst(conn), addr, sizeof(addr));

	if (conn_err) {
		LOG_INF("Connection failed (err %u)\n", conn_err);
		return;
	}

	if (!device_connected) {
		device_connected = true;
		/* stop adv */
		(void)ble_adv_stop();
		(void)k_work_cancel_delayable(&adv_restart_work);
		// led_set_ble_connected(true);
	}

	err = bt_conn_get_info(conn, &info);
	if (err) {
		LOG_INF("Failed to get connection info (err %d)\n", err);
		return;
	}

	if (info.type == BT_CONN_TYPE_LE) {
		const struct bt_conn_le_phy_info *phy_info = info.le.phy;

		LOG_INF("Connected: %s, tx_phy %u, rx_phy %u\n",
			addr, phy_info->tx_phy, phy_info->rx_phy);
	} else {
		LOG_INF("Connected: %s (non-LE?)\n", addr);
	}
}

static void disconnected(struct bt_conn *conn, uint8_t reason)
{
	ARG_UNUSED(conn);

	LOG_INF("Disconnected (reason 0x%02x)\n", reason);

	if (device_connected) {
		device_connected = false;
		/* restart adv via delayed work to avoid race with link teardown */
		(void)k_work_reschedule(&adv_restart_work, K_MSEC(ADV_RESTART_DELAY_MS));
		// led_set_ble_connected(false);
	}
}

static void adv_restart_work_handler(struct k_work *work)
{
	int err;

	ARG_UNUSED(work);

	if (device_connected) {
		return;
	}

	err = ble_adv_start();
	if (err == 0) {
		return;
	}

	LOG_WRN("Adv restart failed (err %d), retry in %u ms", err, ADV_RESTART_RETRY_MS);
	(void)k_work_reschedule(&adv_restart_work, K_MSEC(ADV_RESTART_RETRY_MS));
}

/* Define connection callback */
BT_CONN_CB_DEFINE(conn_callbacks) = {
	.connected = connected,
	.disconnected = disconnected,
};

int ble_adv_start(void)
{
	/*
	 * 最新 Zephyr 推荐：显式构造参数
	 * - CONNECTABLE：可连接
	 * - 使用 FAST_INT_2：常见的快速广播间隔
	 * - 这里不加 BT_LE_ADV_OPT_USE_NAME，因为我们把 NAME 放在 sd[] 里了
	 */
	const struct bt_le_adv_param *adv_param =
		BT_LE_ADV_PARAM(BT_LE_ADV_OPT_SCANNABLE | BT_LE_ADV_OPT_CONN | BT_LE_ADV_OPT_USE_NRPA,
				BT_GAP_ADV_FAST_INT_MIN_2,
				BT_GAP_ADV_FAST_INT_MAX_2,
				NULL);

	int err = bt_le_adv_start(adv_param,
			      ad, ARRAY_SIZE(ad),
			      sd, ARRAY_SIZE(sd));
	if (err) {
		LOG_INF("Failed to start advertising (err %d)\n", err);
		return err;
	}

	LOG_INF("Advertiser started\n");
	return 0;
}

int ble_adv_stop(void)
{
	return bt_le_adv_stop();
}

int ble_adv_init(void)
{
	k_work_init_delayable(&adv_restart_work, adv_restart_work_handler);
	return 0;
}
```

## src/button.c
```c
#include "inc/button.h"

#include <errno.h>
#include <stdint.h>

#include <zephyr/device.h>
#include <zephyr/drivers/gpio.h>
#include <zephyr/kernel.h>
#include <zephyr/logging/log.h>

#include "inc/minneuro_mode.h"

LOG_MODULE_REGISTER(button, LOG_LEVEL_INF);

#define BUTTON_GPIO_NODE DT_NODELABEL(gpio1)
#define BUTTON_HOME_PIN 13u

#define BUTTON_DEBOUNCE_MS 120u

static const struct device *button_gpio;
static struct gpio_callback button_cb;

static struct k_work button_home_work;

static uint32_t button_home_last_ms;

static bool button_is_debounced(uint32_t *last_tick_ms)
{
  uint32_t now_ms = k_uptime_get_32();

  if ((now_ms - *last_tick_ms) < BUTTON_DEBOUNCE_MS) {
    return false;
  }

  *last_tick_ms = now_ms;
  return true;
}

static int button_execute_home(void)
{
#if MINNEURO_DEBUG_MODE
  LOG_INF("button_home ignored in debug mode");
  return 0;
#else
  LOG_INF("button_home has no action in normal mode");
  return 0;
#endif
}

static void button_home_work_handler(struct k_work *work)
{
  ARG_UNUSED(work);
  (void)button_execute_home();
}

static void button_irq_handler(const struct device *dev, struct gpio_callback *cb, uint32_t pins)
{
  ARG_UNUSED(dev);
  ARG_UNUSED(cb);

  if ((pins & BIT(BUTTON_HOME_PIN)) != 0u) {
    if (button_is_debounced(&button_home_last_ms)) {
      (void)k_work_submit(&button_home_work);
    }
  }
}

int button_init(void)
{
  int err;

  button_gpio = DEVICE_DT_GET(BUTTON_GPIO_NODE);
  if (!device_is_ready(button_gpio)) {
    return -ENODEV;
  }

  k_work_init(&button_home_work, button_home_work_handler);

  err = gpio_pin_configure(button_gpio, BUTTON_HOME_PIN, GPIO_INPUT | GPIO_PULL_DOWN | GPIO_ACTIVE_HIGH);
  if (err) {
    return err;
  }

  err = gpio_pin_interrupt_configure(button_gpio, BUTTON_HOME_PIN, GPIO_INT_EDGE_TO_ACTIVE);
  if (err) {
    return err;
  }

  gpio_init_callback(&button_cb, button_irq_handler, BIT(BUTTON_HOME_PIN));
  err = gpio_add_callback(button_gpio, &button_cb);
  if (err) {
    return err;
  }

  LOG_INF("Button ready: home=P1.13 (active high)");
  return 0;
}
```

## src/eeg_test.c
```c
#include "inc/eeg_test.h"

#include <zephyr/kernel.h>
#include <zephyr/logging/log.h>

#include <errno.h>

#include "neuro/inc/eeg_manager.h"

LOG_MODULE_REGISTER(eeg_test, LOG_LEVEL_INF);

enum {
  EEG_TEST_STACK_SIZE = 3072,
  /* Between sd_fs_test (prio 3) and stim_test (prio 6). */
  EEG_TEST_PRIORITY = 5,
  EEG_TEST_LOG_PERIOD_MS = 5000,
};

static struct k_thread s_thread;
K_THREAD_STACK_DEFINE(eeg_test_stack, EEG_TEST_STACK_SIZE);

static void eeg_test_thread(void *arg1, void *arg2, void *arg3)
{
  ARG_UNUSED(arg1);
  ARG_UNUSED(arg2);
  ARG_UNUSED(arg3);

  unsigned frames_ok = 0u;
  unsigned read_eagain = 0u;

  k_msleep(150);

  (void)eeg_manager_init();

  const eeg_manager_config_t cfg = {
    .sample_rate_hz = TASK_EEG_DEFAULT_SAMPLE_RATE_HZ,
  };

  int err = eeg_manager_start(cfg);
  if (err != 0) {
    LOG_ERR("eeg_test: eeg_manager_start failed (%d)", err);
    return;
  }

  LOG_INF("eeg_test: streaming @ %u Hz (read loop)", (unsigned int)cfg.sample_rate_hz);

  int64_t next_log_ms = k_uptime_get() + EEG_TEST_LOG_PERIOD_MS;

  for (;;) {
    eeg_manager_frame_t frame;
    err = eeg_manager_read_frame(&frame);
    if (err == 0) {
      frames_ok++;
    } else if (err == -EAGAIN) {
      read_eagain++;
      k_msleep(2);
      continue;
    } else {
      LOG_WRN("eeg_test: eeg_manager_read_frame err %d", err);
      k_msleep(10);
      continue;
    }

    const int64_t now = k_uptime_get();
    if (now >= next_log_ms) {
      LOG_INF("eeg_test: frames_ok=%u eagain_cycles=%u last_n=%u", frames_ok,
              read_eagain, (unsigned int)frame.sample_count);
      next_log_ms = now + EEG_TEST_LOG_PERIOD_MS;
    }

    /* Timer drives samples slower than tight loop — yield so SPI workers run. */
    k_yield();
  }
}

int eeg_test_start(void)
{
  k_thread_create(&s_thread, eeg_test_stack, K_THREAD_STACK_SIZEOF(eeg_test_stack), eeg_test_thread,
                  NULL,
                  NULL, NULL, EEG_TEST_PRIORITY, 0, K_NO_WAIT);
  k_thread_name_set(&s_thread, "eeg_test");
  return 0;
}
```

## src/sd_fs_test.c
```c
#include "inc/sd_fs_test.h"

#include <stddef.h>
#include <stdint.h>
#include <string.h>

#include <zephyr/kernel.h>
#include <zephyr/logging/log.h>
#include <zephyr/sys/printk.h>

#include "driver/file.h"

LOG_MODULE_REGISTER(sd_fs_test, LOG_LEVEL_INF);

/*
 * Continuous SD write benchmark (after smoke checks). Tune chunk/rounds in build flags:
 *   -DSD_FS_TEST_PERF_ENABLE=0   disable
 *   -DSD_FS_PERF_CHUNK_BYTES=1024 -DSD_FS_PERF_ROUNDS=500
 */
#ifndef SD_FS_TEST_PERF_ENABLE
#define SD_FS_TEST_PERF_ENABLE 1
#endif
#ifndef SD_FS_PERF_CHUNK_BYTES
#define SD_FS_PERF_CHUNK_BYTES 512u
#endif
#ifndef SD_FS_PERF_ROUNDS
#define SD_FS_PERF_ROUNDS 200u
#endif
#ifndef SD_FS_TEST_APPEND_LOOP_MS
#define SD_FS_TEST_APPEND_LOOP_MS 3000
#endif

enum {
  /* f_mount / mkfs need stack; prio 3 runs ahead of many stack threads (e.g. prio ~8). */
  SD_FS_TEST_STACK_SIZE = 4096,
  SD_FS_TEST_PRIORITY = 3,
};

#define TEST_APPEND_FILE "/MinNeuroStorage:/fs_test/sd_fs_test.txt"

#if SD_FS_TEST_PERF_ENABLE
#define PERF_BULK_PATH "/MinNeuroStorage:/fs_test/sd_perf_bulk.bin"
static uint8_t s_perf_chunk[SD_FS_PERF_CHUNK_BYTES];
#endif
static const char s_payload[] = " hello Gong He ,I am here bro :)!\nsecond line\n";
static struct k_thread s_thread;
K_THREAD_STACK_DEFINE(sd_fs_test_stack, SD_FS_TEST_STACK_SIZE);

static void sd_fs_test_thread(void *arg1, void *arg2, void *arg3)
{
  //防编译警告
  ARG_UNUSED(arg1);
  ARG_UNUSED(arg2);
  ARG_UNUSED(arg3);

  printk("sd loop thread spawned\n");
  k_msleep(235);

  LOG_INF("begin");

  LOG_INF("file_init (SPI mount)...");
  int rc = file_init();
  LOG_INF("sd_fs_test: file_init returned %d", rc);
  if (rc != 0) {
    LOG_ERR("sd_fs_test: file_init failed (%d)", rc);
    return;
  }

  LOG_INF("sd_fs_test: card_detect=%d (0=maybe no CD routed / open socket)",
          file_is_card_inserted());

  rc = file_create(TEST_APPEND_FILE);
  if (rc != 0) {
    LOG_ERR("sd_fs_test: file_create failed (%d)", rc);
    return;
  }

  rc = file_append(TEST_APPEND_FILE, (const uint8_t *)s_payload, sizeof(s_payload) - 1u);
  if (rc != 0) {
    LOG_ERR("sd_fs_test: file_append failed (%d)", rc);
    return;
  }

  rc = file_sync_all();
  if (rc != 0) {
    LOG_ERR("sd_fs_test: file_sync_all failed (%d)", rc);
    return;
  }

  char rb[sizeof(s_payload) + 16];
  size_t n = 0;
  rc = file_read_text(TEST_APPEND_FILE, rb, sizeof(rb), &n);
  if (rc != 0) {
    LOG_ERR("sd_fs_test: file_read_text failed (%d)", rc);
    return;
  }

  if (n != sizeof(s_payload) - 1u || memcmp(rb, s_payload, n) != 0) {
    LOG_ERR("sd_fs_test: readback mismatch (len=%zu expected=%zu)",
            n, sizeof(s_payload) - 1u);
    return;
  }

  LOG_INF("sd_fs_test: append + readback OK (%zu bytes)", n);
  LOG_INF("sd_fs_test: readback content: %s", rb);

  char task_dir[96];
  char seg_path[128];
  LOG_INF("sd_fs_test: phase2 mkdir task dir...");
  rc = file_create_task_dir("sdsmoke", task_dir, sizeof(task_dir));
  if (rc != 0) {
    LOG_ERR("sd_fs_test: file_create_task_dir failed (%d)", rc);
    return;
  }
  LOG_INF("sd_fs_test: task_dir=%s", task_dir);

  LOG_INF("sd_fs_test: phase2 segment path...");
  rc = file_make_segment_path(task_dir, "seg", 0u, seg_path, sizeof(seg_path));
  if (rc != 0) {
    LOG_ERR("sd_fs_test: file_make_segment_path failed (%d)", rc);
    return;
  }

  LOG_INF("sd_fs_test: phase2 append segment...");
  static const uint8_t seg_blob[] = {0x01, 0x02, 0x03};
  rc = file_append(seg_path, seg_blob, sizeof(seg_blob));
  if (rc != 0) {
    LOG_ERR("sd_fs_test: segment file_append failed (%d)", rc);
    return;
  }

  LOG_INF("sd_fs_test: phase2 sync...");
  rc = file_sync_all();
  if (rc != 0) {
    LOG_ERR("sd_fs_test: second sync failed (%d)", rc);
    return;
  }

  LOG_INF("sd_fs_test: task dir OK: %s", seg_path);

#if SD_FS_TEST_PERF_ENABLE
  LOG_INF("sd_fs_test: perf: bulk append (%u B x %u rounds) → %s", (unsigned int)sizeof(s_perf_chunk),
          SD_FS_PERF_ROUNDS, PERF_BULK_PATH);
  memset(s_perf_chunk, 0xA5u, sizeof(s_perf_chunk));

  rc = file_create(PERF_BULK_PATH);
  if (rc != 0) {
    LOG_ERR("sd_fs_test: perf file_create failed (%d) — delete %s if it exists stale", rc,
            PERF_BULK_PATH);
    return;
  }

  int64_t t_append0 = k_uptime_get();
  for (uint32_t i = 0; i < SD_FS_PERF_ROUNDS; i++) {
    rc = file_append(PERF_BULK_PATH, s_perf_chunk, sizeof(s_perf_chunk));
    if (rc != 0) {
      LOG_ERR("sd_fs_test: perf append round %u failed (%d)", (unsigned int)i, rc);
      return;
    }
  }
  int64_t t_append1 = k_uptime_get();
  int64_t dt_ms = t_append1 - t_append0;
  uint64_t total_bytes = (uint64_t)SD_FS_PERF_ROUNDS * (uint64_t)sizeof(s_perf_chunk);
  if (dt_ms > 0) {
    const double secs = (double)dt_ms / 1000.0;
    const double kib_s = (double)total_bytes / 1024.0 / secs;
    const double mbit_s = (double)total_bytes * 8.0 / secs / 1e6;
    LOG_INF("sd_fs_test: perf append_done total_bytes=%llu dt_ms=%lld (~%.2f KiB/s, ~%.3f Mbit/s)",
            (unsigned long long)total_bytes, (long long)dt_ms, kib_s, mbit_s);
  } else {
    LOG_INF("sd_fs_test: perf append_done total_bytes=%llu dt_ms=<1", (unsigned long long)total_bytes);
  }

  int64_t t_sync0 = k_uptime_get();
  rc = file_sync_all();
  int64_t t_sync1 = k_uptime_get();
  if (rc != 0) {
    LOG_ERR("sd_fs_test: perf file_sync_all failed (%d)", rc);
    return;
  }
  LOG_INF("sd_fs_test: perf sync_all dt_ms=%lld", (long long)(t_sync1 - t_sync0));
#endif /* SD_FS_TEST_PERF_ENABLE */

  LOG_INF("sd_fs_test: smoke complete; infinite append loop (interval=%d ms, tail readback)...",
          SD_FS_TEST_APPEND_LOOP_MS);

  static char s_loop_tail_rb[sizeof(s_payload) + 24];
  const size_t payload_u8_len = sizeof(s_payload) - 1u;

  for (unsigned iter = 1;; iter++) {
    int64_t t0 = k_uptime_get();

    rc = file_append(TEST_APPEND_FILE, (const uint8_t *)s_payload, payload_u8_len);
    int64_t t_after_append = k_uptime_get();

    if (rc != 0) {
      LOG_ERR("sd_fs_test: loop file_append iter=%u failed (%d)", iter, rc);
      k_msleep(SD_FS_TEST_APPEND_LOOP_MS);
      continue;
    }

    rc = file_sync_all();
    int64_t t_after_sync = k_uptime_get();

    if (rc != 0) {
      LOG_ERR("sd_fs_test: loop file_sync_all iter=%u failed (%d)", iter, rc);
      k_msleep(SD_FS_TEST_APPEND_LOOP_MS);
      continue;
    }

    LOG_INF(
        "sd_fs_test: loop iter=%u store append_ms=%lld sync_ms=%lld total_ms=%lld (bytes=%zu)",
        iter, (long long)(t_after_append - t0),
        (long long)(t_after_sync - t_after_append),
        (long long)(t_after_sync - t0),
        payload_u8_len);

    size_t tail_n = 0;
    int64_t tr0 = k_uptime_get();
    rc = file_read_tail_text(TEST_APPEND_FILE, s_loop_tail_rb, sizeof(s_loop_tail_rb),
                             payload_u8_len, &tail_n);
    int64_t tr1 = k_uptime_get();
    if (rc != 0) {
      LOG_ERR("sd_fs_test: loop file_read_tail_text iter=%u failed (%d)", iter, rc);
    } else {
      if (tail_n != payload_u8_len ||
          memcmp(s_loop_tail_rb, s_payload, payload_u8_len) != 0) {
        LOG_WRN("sd_fs_test: loop tail mismatch iter=%u got_len=%zu (expected %zu)", iter,
                tail_n, payload_u8_len);
      }
      LOG_INF("sd_fs_test: loop tail read_tail_ms=%lld last %zu B: \"%.*s\"",
              (long long)(tr1 - tr0), tail_n, (int)tail_n,
              s_loop_tail_rb);
    }

    k_msleep(SD_FS_TEST_APPEND_LOOP_MS);
  }
}

int sd_fs_test_start(void)
{
  k_thread_create(&s_thread, sd_fs_test_stack, K_THREAD_STACK_SIZEOF(sd_fs_test_stack), sd_fs_test_thread,
                  NULL, NULL,
                  NULL, SD_FS_TEST_PRIORITY, 0, K_NO_WAIT);
  k_thread_name_set(&s_thread, "sd_fs_test");
  return 0;
}
```
